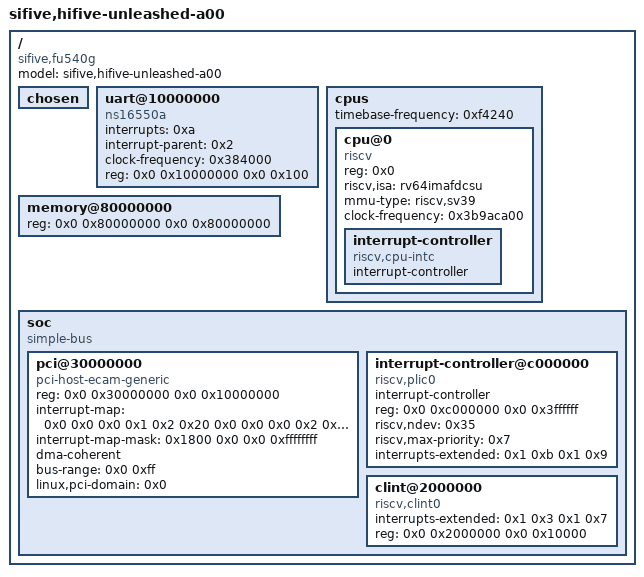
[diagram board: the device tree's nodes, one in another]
/dts-v1/;

/memreserve/	0x0000000000000000 0x0000000000010000;
/ {
	#address-cells = <0x2>;
	#size-cells = <0x2>;
	compatible = "sifive,fu540g";
	model = "sifive,hifive-unleashed-a00";

	chosen {
	};

	uart@10000000 {
		interrupts = <0xa>;
		interrupt-parent = <0x2>;
		clock-frequency = <0x384000>;
		reg = <0x0 0x10000000 0x0 0x100>;
		compatible = "ns16550a";
	};

	cpus {
		#address-cells = <0x1>;
		#size-cells = <0x0>;
		timebase-frequency = <0xf4240>;

		cpu@0 {
			device_type = "cpu";
			reg = <0x0>;
			status = "okay";
			compatible = "riscv";
			riscv,isa = "rv64imafdcsu";
			mmu-type = "riscv,sv39";
			clock-frequency = <0x3b9aca00>;

			interrupt-controller {
				#interrupt-cells = <0x1>;
				interrupt-controller;
				compatible = "riscv,cpu-intc";
				linux,phandle = <0x1>;
				phandle = <0x1>;
			};
		};
	};

	memory@80000000 {
		device_type = "memory";
		reg = <0x0 0x80000000 0x0 0x80000000>;
	};

	soc {
		#address-cells = <0x2>;
		#size-cells = <0x2>;
		compatible = "simple-bus";
		ranges;

		pci@30000000 {
			compatible = "pci-host-ecam-generic";
			device_type = "pci";
			#address-cells = <0x3>;
			#size-cells = <0x2>;
			#interrupt-cells = <0x1>;
			reg = <0x0 0x30000000 0x0 0x10000000>;
			ranges = <0x1000000 0x0 0x0 0x0 0x2f000000 0x0 0x10000 0x2000000 0x0 0x40000000 0x0 0x40000000 0x0 0x10000000>;
			interrupt-map = <0x0 0x0 0x0 0x1 0x2 0x20 0x0 0x0 0x0 0x2 0x2 0x21 0x0 0x0 0x0 0x3 0x2 0x22 0x0 0x0 0x0 0x4 0x2 0x23 0x800 0x0 0x0 0x1 0x2 0x21 0x800 0x0 0x0 0x2 0x2 0x22 0x800 0x0 0x0 0x3 0x2 0x23 0x800 0x0 0x0 0x4 0x2 0x20 0x1000 0x0 0x0 0x1 0x2 0x22 0x1000 0x0 0x0 0x2 0x2 0x23 0x1000 0x0 0x0 0x3 0x2 0x20 0x1000 0x0 0x0 0x4 0x2 0x21 0x1800 0x0 0x0 0x1 0x2 0x23 0x1800 0x0 0x0 0x2 0x2 0x20 0x1800 0x0 0x0 0x3 0x2 0x21 0x1800 0x0 0x0 0x4 0x2 0x22>;
			interrupt-map-mask = <0x1800 0x0 0x0 0xffffffff>;
			dma-coherent;
			bus-range = <0x0 0xff>;
			linux,pci-domain = <0x0>;
		};

		interrupt-controller@c000000 {
			compatible = "riscv,plic0";
			#interrupt-cells = <0x1>;
			#address-cells = <0x0>;
			interrupt-controller;
			reg = <0x0 0xc000000 0x0 0x3ffffff>;
			phandle = <0x2>;
			linux,phandle = <0x2>;
			riscv,ndev = <0x35>;
			riscv,max-priority = <0x7>;
			reg-names = "control";
			interrupts-extended = <0x1 0xb 0x1 0x9>;
		};

		clint@2000000 {
			interrupts-extended = <0x1 0x3 0x1 0x7>;
			reg = <0x0 0x2000000 0x0 0x10000>;
			compatible = "riscv,clint0";
		};
	};
};
